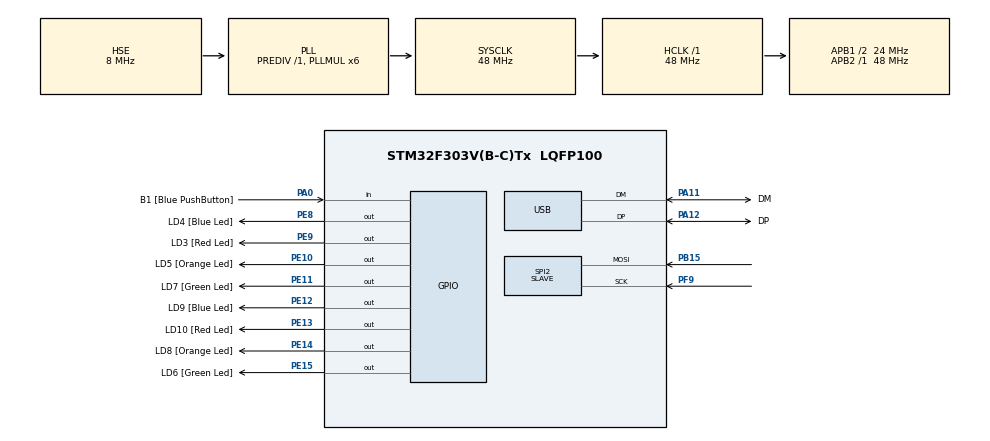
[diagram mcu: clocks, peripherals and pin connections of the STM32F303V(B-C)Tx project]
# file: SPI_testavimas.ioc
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Mcu.Family=STM32F3
Mcu.Name=STM32F303V(B-C)Tx
Mcu.Package=LQFP100
NVIC.PriorityGroup=NVIC_PRIORITYGROUP_0
NVIC.SPI2_IRQn=true\:0\:0\:false\:false\:true\:true\:true\:true
PA0.GPIO_Label=B1 [Blue PushButton]
PA0.Signal=GPIO_Input
PA11.GPIO_Label=DM
PA11.Mode=Device
PA11.Signal=USB_DM
PA12.GPIO_Label=DP
PA12.Mode=Device
PA12.Signal=USB_DP
PA13.GPIO_Label=SWDIO
PA13.Mode=Serial_Wire
PA13.Signal=SYS_JTMS-SWDIO
PA14.GPIO_Label=SWCLK
PA14.Mode=Serial_Wire
PA14.Signal=SYS_JTCK-SWCLK
PB15.Mode=RX_Only_Simplex_Unidirect_Slave
PB15.Signal=SPI2_MOSI
PB3.GPIO_Label=SWO
PB3.Signal=SYS_JTDO-TRACESWO
PC14-OSC32_IN.GPIO_Label=OSC32_IN
PC14-OSC32_IN.Signal=RCC_OSC32_IN
PC15-OSC32_OUT.GPIO_Label=OSC32_OUT
PC15-OSC32_OUT.Signal=RCC_OSC32_OUT
PE10.GPIO_Label=LD5 [Orange Led]
PE10.Signal=GPIO_Output
PE11.GPIO_Label=LD7 [Green Led]
PE11.Signal=GPIO_Output
PE12.GPIO_Label=LD9 [Blue Led]
PE12.Signal=GPIO_Output
PE13.GPIO_Label=LD10 [Red Led]
PE13.Signal=GPIO_Output
PE14.GPIO_Label=LD8 [Orange Led]
PE14.Signal=GPIO_Output
PE15.GPIO_Label=LD6 [Green Led]
PE15.Signal=GPIO_Output
PE8.GPIO_Label=LD4 [Blue Led]
PE8.Signal=GPIO_Output
PE9.GPIO_Label=LD3 [Red Led]
PE9.Signal=GPIO_Output
PF0-OSC_IN.GPIO_Label=OSC_IN
PF0-OSC_IN.Mode=HSE-External-Clock-Source
PF0-OSC_IN.Signal=RCC_OSC_IN
PF1-OSC_OUT.GPIO_Label=OSC_OUT
PF1-OSC_OUT.Signal=RCC_OSC_OUT
PF9.Mode=RX_Only_Simplex_Unidirect_Slave
PF9.Signal=SPI2_SCK
ProjectManager.HeapSize=0x200
ProjectManager.StackSize=0x400
ProjectManager.TargetToolchain=MDK-ARM V5.32
RCC.AHBFreq_Value=48000000
RCC.APB1CLKDivider=RCC_HCLK_DIV2
RCC.APB1Freq_Value=24000000
RCC.APB1TimFreq_Value=48000000
RCC.APB2Freq_Value=48000000
RCC.APB2TimFreq_Value=48000000
RCC.CortexFreq_Value=48000000
RCC.HCLKFreq_Value=48000000
RCC.HSE_VALUE=8000000
RCC.HSI_VALUE=8000000
RCC.LSE_VALUE=32768
RCC.PLLMUL=RCC_PLL_MUL6
RCC.SYSCLKFreq_VALUE=48000000
RCC.SYSCLKSourceVirtual=RCC_SYSCLKSOURCE_PLLCLK
RCC.USBFreq_Value=48000000
SPI2.DataSize=SPI_DATASIZE_16BIT
SPI2.Direction=SPI_DIRECTION_2LINES_RXONLY
SPI2.Mode=SPI_MODE_SLAVE
SPI2.VirtualType=VM_SLAVE
board=STM32F3DISCOVERY

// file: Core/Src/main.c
/* USER CODE BEGIN Header */
/**
  ******************************************************************************
  * @file           : main.c
  * @brief          : Main program body
  ******************************************************************************
  * @attention
  *
  * Copyright (c) 2023 STMicroelectronics.
  * All rights reserved.
  *
  * This software is licensed under terms that can be found in the LICENSE file
  * in the root directory of this software component.
  * If no LICENSE file comes with this software, it is provided AS-IS.
  *
  ******************************************************************************
  */
/* USER CODE END Header */
#include "main.h"

SPI_HandleTypeDef hspi2;

PCD_HandleTypeDef hpcd_USB_FS;

void SystemClock_Config(void);
static void MX_GPIO_Init(void);
static void MX_USB_PCD_Init(void);
static void MX_SPI2_Init(void);

/* USER CODE BEGIN 0 */
uint8_t input_data[4] = {0};

void HAL_SPI_RxCpltCallback(SPI_HandleTypeDef * hspi)
{
	//https://deepbluembedded.com/stm32-spi-tutorial/
	if(hspi == &hspi2){
		HAL_GPIO_TogglePin(LD4_GPIO_Port, LD4_Pin);
	}
}

/* USER CODE END 0 */

int main(void)
{

  /* MCU Configuration--------------------------------------------------------*/

  /* Reset of all peripherals, Initializes the Flash interface and the Systick. */
  HAL_Init();

  /* Configure the system clock */
  SystemClock_Config();

  /* Initialize all configured peripherals */
  MX_GPIO_Init();
  MX_USB_PCD_Init();
  MX_SPI2_Init();

  /* Infinite loop */
  while (1)
  {

    /* USER CODE BEGIN 3 */
		HAL_SPI_Receive_IT(&hspi2, input_data, 1);

  }
  /* USER CODE END 3 */
}

void SystemClock_Config(void)
{
  RCC_OscInitTypeDef RCC_OscInitStruct = {0};
  RCC_ClkInitTypeDef RCC_ClkInitStruct = {0};
  RCC_PeriphCLKInitTypeDef PeriphClkInit = {0};

  /** Initializes the RCC Oscillators according to the specified parameters
  * in the RCC_OscInitTypeDef structure.
  */
  RCC_OscInitStruct.OscillatorType = RCC_OSCILLATORTYPE_HSE;
  RCC_OscInitStruct.HSEState = RCC_HSE_BYPASS;
  RCC_OscInitStruct.HSEPredivValue = RCC_HSE_PREDIV_DIV1;
  RCC_OscInitStruct.HSIState = RCC_HSI_ON;
  RCC_OscInitStruct.PLL.PLLState = RCC_PLL_ON;
  RCC_OscInitStruct.PLL.PLLSource = RCC_PLLSOURCE_HSE;
  RCC_OscInitStruct.PLL.PLLMUL = RCC_PLL_MUL6;
  if (HAL_RCC_OscConfig(&RCC_OscInitStruct) != HAL_OK)
  {
    Error_Handler();
  }

  /** Initializes the CPU, AHB and APB buses clocks
  */
  RCC_ClkInitStruct.ClockType = RCC_CLOCKTYPE_HCLK|RCC_CLOCKTYPE_SYSCLK
                              |RCC_CLOCKTYPE_PCLK1|RCC_CLOCKTYPE_PCLK2;
  RCC_ClkInitStruct.SYSCLKSource = RCC_SYSCLKSOURCE_PLLCLK;
  RCC_ClkInitStruct.AHBCLKDivider = RCC_SYSCLK_DIV1;
  RCC_ClkInitStruct.APB1CLKDivider = RCC_HCLK_DIV2;
  RCC_ClkInitStruct.APB2CLKDivider = RCC_HCLK_DIV1;

  if (HAL_RCC_ClockConfig(&RCC_ClkInitStruct, FLASH_LATENCY_1) != HAL_OK)
  {
    Error_Handler();
  }
  PeriphClkInit.PeriphClockSelection = RCC_PERIPHCLK_USB;
  PeriphClkInit.USBClockSelection = RCC_USBCLKSOURCE_PLL;
  if (HAL_RCCEx_PeriphCLKConfig(&PeriphClkInit) != HAL_OK)
  {
    Error_Handler();
  }
}

static void MX_SPI2_Init(void)
{

  /* SPI2 parameter configuration*/
  hspi2.Instance = SPI2;
  hspi2.Init.Mode = SPI_MODE_SLAVE;
  hspi2.Init.Direction = SPI_DIRECTION_2LINES_RXONLY;
  hspi2.Init.DataSize = SPI_DATASIZE_16BIT;
  hspi2.Init.CLKPolarity = SPI_POLARITY_LOW;
  hspi2.Init.CLKPhase = SPI_PHASE_1EDGE;
  hspi2.Init.NSS = SPI_NSS_SOFT;
  hspi2.Init.FirstBit = SPI_FIRSTBIT_MSB;
  hspi2.Init.TIMode = SPI_TIMODE_DISABLE;
  hspi2.Init.CRCCalculation = SPI_CRCCALCULATION_DISABLE;
  hspi2.Init.CRCPolynomial = 7;
  hspi2.Init.CRCLength = SPI_CRC_LENGTH_DATASIZE;
  hspi2.Init.NSSPMode = SPI_NSS_PULSE_DISABLE;
  if (HAL_SPI_Init(&hspi2) != HAL_OK)
  {
    Error_Handler();
  }

}

static void MX_USB_PCD_Init(void)
{

  hpcd_USB_FS.Instance = USB;
  hpcd_USB_FS.Init.dev_endpoints = 8;
  hpcd_USB_FS.Init.speed = PCD_SPEED_FULL;
  hpcd_USB_FS.Init.phy_itface = PCD_PHY_EMBEDDED;
  hpcd_USB_FS.Init.low_power_enable = DISABLE;
  hpcd_USB_FS.Init.battery_charging_enable = DISABLE;
  if (HAL_PCD_Init(&hpcd_USB_FS) != HAL_OK)
  {
    Error_Handler();
  }

}

static void MX_GPIO_Init(void)
{
  GPIO_InitTypeDef GPIO_InitStruct = {0};

  /* GPIO Ports Clock Enable */
  __HAL_RCC_GPIOC_CLK_ENABLE();
  __HAL_RCC_GPIOF_CLK_ENABLE();
  __HAL_RCC_GPIOA_CLK_ENABLE();
  __HAL_RCC_GPIOE_CLK_ENABLE();
  __HAL_RCC_GPIOB_CLK_ENABLE();

  /*Configure GPIO pin Output Level */
  HAL_GPIO_WritePin(GPIOE, LD4_Pin|LD3_Pin|LD5_Pin|LD7_Pin
                          |LD9_Pin|LD10_Pin|LD8_Pin|LD6_Pin, GPIO_PIN_RESET);

  /*Configure GPIO pin : B1_Pin */
  GPIO_InitStruct.Pin = B1_Pin;
  GPIO_InitStruct.Mode = GPIO_MODE_INPUT;
  GPIO_InitStruct.Pull = GPIO_NOPULL;
  HAL_GPIO_Init(B1_GPIO_Port, &GPIO_InitStruct);

  /*Configure GPIO pins : LD4_Pin LD3_Pin LD5_Pin LD7_Pin
                           LD9_Pin LD10_Pin LD8_Pin LD6_Pin */
  GPIO_InitStruct.Pin = LD4_Pin|LD3_Pin|LD5_Pin|LD7_Pin
                          |LD9_Pin|LD10_Pin|LD8_Pin|LD6_Pin;
  GPIO_InitStruct.Mode = GPIO_MODE_OUTPUT_PP;
  GPIO_InitStruct.Pull = GPIO_NOPULL;
  GPIO_InitStruct.Speed = GPIO_SPEED_FREQ_LOW;
  HAL_GPIO_Init(GPIOE, &GPIO_InitStruct);

}

void Error_Handler(void)
{
  __disable_irq();
  while (1)
  {
  }
}
